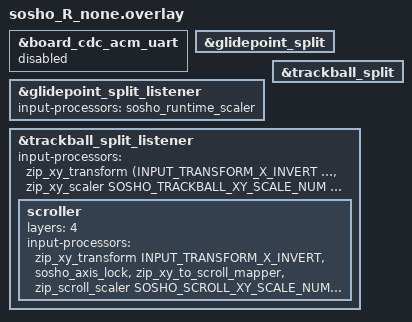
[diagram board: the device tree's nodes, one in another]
#include "sosho_R.dtsi"
#include <dt-bindings/zmk/input_transform.h>
#include <input/processors.dtsi>

/* Blank right module: keep the Central split-input listeners so this profile
 * can be paired with either a trackpad or trackball peripheral. */
/* Keep only the dedicated Studio RPC CDC-ACM endpoint visible to the web
 * editor; the board console endpoint is not used by this firmware. */
&board_cdc_acm_uart { status = "disabled"; };

&glidepoint_split { status = "okay"; };
&glidepoint_split_listener {
    status = "okay";
    /* Keep the peripheral's official relative path and primary tap. The
     * blank module does not reinterpret coordinates or synthesize gestures. */
    input-processors = <&sosho_runtime_scaler>;
};

&trackball_split { status = "okay"; };
&trackball_split_listener {
    status = "okay";
    input-processors = <&zip_xy_transform (INPUT_TRANSFORM_X_INVERT | INPUT_TRANSFORM_Y_INVERT)>,
                       <&zip_xy_scaler SOSHO_TRACKBALL_XY_SCALE_NUM SOSHO_TRACKBALL_XY_SCALE_DEN>;
    scroller {
        layers = <4>;
        input-processors = <&zip_xy_transform INPUT_TRANSFORM_X_INVERT>,
                           <&sosho_axis_lock>,
                           <&zip_xy_to_scroll_mapper>,
                           <&zip_scroll_scaler SOSHO_SCROLL_XY_SCALE_NUM SOSHO_SCROLL_XY_SCALE_DEN>;
    };
};
